# nrf7120E_enga_flpr register map
Vendor: Nordic Semiconductor; Series: nrf71; File version: 1
Registers are 32-bit, read-write, reset 0x0 unless marked. A register's access mark holds for its fields unless they carry their own. Offsets are from the block's base; [hi:lo] are bit positions; lines under a group give offsets from that group; {n}, {i} and the like mark numbered series; 'fields as' and 'values as' point back to an identical list.

## GLOBAL_WICR_NS — Wi-Fi Information Configuration Registers
Base 0x003FD000
0x00 FIRMWARE group — Unspecified
  0x00 LMACINITPC reset 0x28080000 — Boot address for LMAC processor (defaults to start of Wi-Fi core ROM_0)
    [31:0] INITPC — LMAC boot vector
  0x04 UMACINITPC reset 0x28180000 — Boot address for UMAC processor (defaults to start of Wi-Fi core ROM_1)
    [31:0] INITPC — UMAC boot vector
  0x08 LMACROMPATCHADDR — Address in MRAM for LMAC ROM patch
    [31:0] Address — LMAC ROM patch address
  0x0C UMACROMPATCHADDR — Address in MRAM for UMAC ROM patch
    [31:0] Address — UMAC ROM patch address
0x80 IPCCONFIG group — Unspecified
  0x00 COMMANDMBOXADDR — Base address of command mailbox
    [31:0] ADDRESS — Base address of mailbox
  0x04 COMMANDMBOXSIZE — Size of command mailbox in bytes
    [31:0] SIZE — Size in bytes
  0x08 EVENTMBOXADDR — Base address of event mailbox
    [31:0] ADDRESS — Base address of mailbox
  0x0C EVENTMBOXSIZE — Size of event mailbox in bytes
    [31:0] SIZE — Size in bytes
  0x10 SPAREMBOXADDR — Base address of spare mailbox
    [31:0] ADDRESS — Base address of mailbox
  0x14 SPAREMBOXSIZE — Size of spare mailbox in bytes
    [31:0] SIZE — Size in bytes
0x100 VTFDATA reset 0xFFFFFFFF — Pointer to memory location containing VTF data from the VTF monitoring system
  [31:0] ADDRESS — Address of the VTF monitoring data in RAM
0x104 RFPARAMSDATAADDR — Base address of RF parameter data
  [31:0] ADDRESS
0x108 RFPARAMSDATASIZE — Size of RF parameter data in bytes
  [31:0] SIZE — Size in bytes

## VPRCLIC_NS — VPR CLIC registers
Base 0xF0000000
0x00 CLIC group — Unspecified
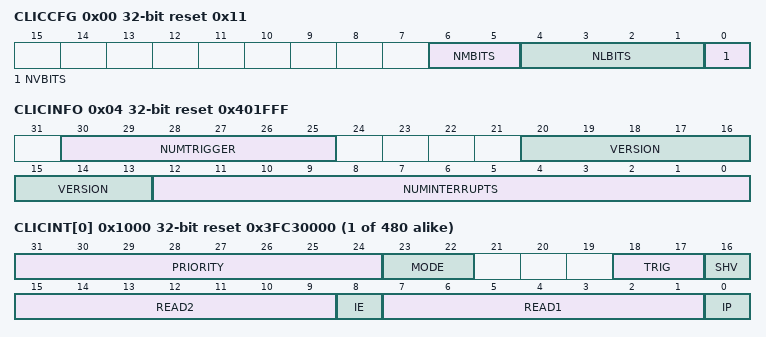
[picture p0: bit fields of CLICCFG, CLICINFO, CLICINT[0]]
  0x00 CLICCFG ro reset 0x11 — CLIC configuration.
    [6:5] NMBITS — Interrupt privilege mode.
      0=ModeM (All interrupts are M-mode only)
    [4:1] NLBITS — Interrupt level encoding.
      8=Eight (8 bits = interrupt levels encoded in eight bits)
    [0] NVBITS — Selective interrupt hardware vectoring.
      1=Implemented (Selective interrupt hardware vectoring is implemented)
  0x04 CLICINFO ro reset 0x401FFF — CLIC information.
    [30:25] NUMTRIGGER — Number of maximum interrupt triggers supported
    [20:13] VERSION
    [12:0] NUMINTERRUPTS — Maximum number of interrupts supported.
  {0x1000+4j} CLICINT[{j}] (j=0..479) reset 0x3FC30000 — Description collection: Interrupt control register for IRQ number [n].
    [31:24] PRIORITY — Interrupt priority level
      63=PRIO3F (Priority level 0x3F); 127=PRIO7F (Priority level 0x7F); 191=PRIOBF (Priority level 0xBF); 255=PRIOFF (Priority level 0xFF); 63=PRIOLEVEL0 (Deprecated enumerator - Priority level 0); 127=PRIOLEVEL1 (Deprecated enumerator - Priority level 1); 191=PRIOLEVEL2 (Deprecated enumerator - Priority level 2); 255=PRIOLEVEL3 (Deprecated enumerator - Priority level 3)
    [23:22] MODE ro — Privilege mode.
      3=MachineMode
    [18:17] TRIG ro — Trigger type and polarity for each interrupt input.
      1=EdgeTriggered (Interrupts are edge-triggered)
    [16] SHV ro — Selective Hardware Vectoring.
      1=Vectored (Hardware vectored)
    [15:9] READ2 ro — Read as 0, write ignored.
    [8] IE — Interrupt enable bit.
      0=Disabled (Interrupt disabled); 1=Enabled (Interrupt enabled)
    [7:1] READ1 ro — Read as 0, write ignored.
    [0] IP — Interrupt Pending bit.
      0=NotPending (Interrupt not pending); 1=Pending (Interrupt pending)

## GLOBAL_DPPIC00_NS — Distributed programmable peripheral interconnect controller 0
Base 0x40042000; alternate view of GLOBAL_USBHSCORE_NS
Same registers: GLOBAL_DPPIC10_NS 0x40082000, GLOBAL_DPPIC20_NS 0x400C2000, GLOBAL_DPPIC30_NS 0x40102000, GLOBAL_DPPIC00_S 0x50042000 (alternate view of GLOBAL_USBHSCORE_S), GLOBAL_DPPIC10_S 0x50082000, GLOBAL_DPPIC20_S 0x500C2000, GLOBAL_DPPIC30_S 0x50102000
{0x0+8i} TASKS_CHG[{i}] (i=0..5) group — Channel group tasks
  0x00 EN wo — Description cluster: Enable channel group n
    [0] EN — Enable channel group n
      1=Trigger task
  0x04 DIS wo — Description cluster: Disable channel group n
    [0] DIS — Disable channel group n
      1=Trigger task
{0x80+8i} SUBSCRIBE_CHG[{i}] (i=0..5) group — Subscribe configuration for tasks
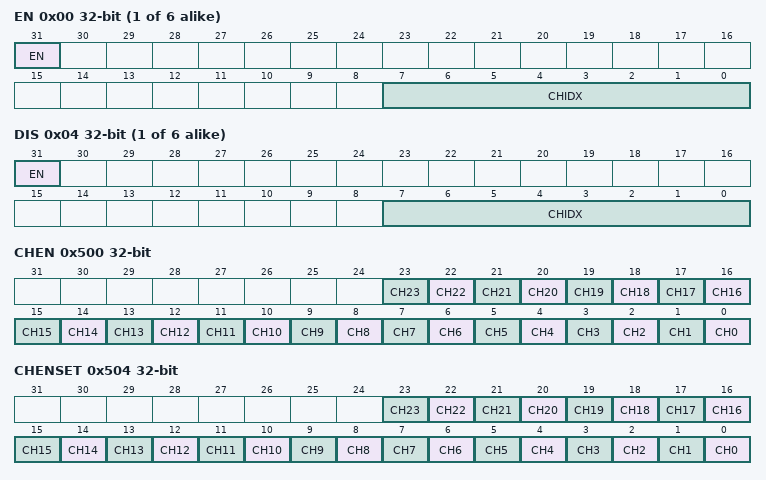
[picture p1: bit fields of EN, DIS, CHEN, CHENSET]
  0x00 EN — Description cluster: Subscribe configuration for task CHG[n].EN
    [31] EN
      0=Disabled (Disable subscription); 1=Enabled (Enable subscription)
    [7:0] CHIDX — DPPI channel that task CHG[n].EN will subscribe to
  0x04 DIS — Description cluster: Subscribe configuration for task CHG[n].DIS
    [31] EN
      values as SUBSCRIBE_CHG[0].EN.EN
    [7:0] CHIDX — DPPI channel that task CHG[n].DIS will subscribe to
0x500 CHEN — Channel enable register
  [all] fields
    0=Disabled (Disable channel); 1=Enabled (Enable channel)
  [n] CH{n} (n=0..23) — Enable or disable channel {n}
0x504 CHENSET write-1-sets — Channel enable set register
  [all] fields
    on read: 0=Disabled (Read: Channel disabled); 1=Enabled (Read: Channel enabled) | on write: 1=Set (Write: Enable channel)
  [n] CH{n} (n=0..23) — Channel {n} enable set register. Writing 0 has no effect.
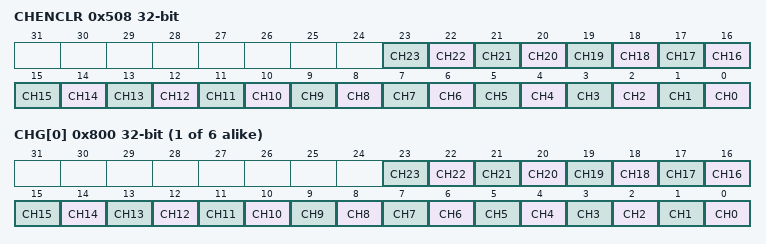
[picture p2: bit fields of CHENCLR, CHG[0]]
0x508 CHENCLR write-1-clears — Channel enable clear register
  [all] fields
    on read: 0=Disabled (Read: Channel disabled); 1=Enabled (Read: Channel enabled) | on write: 1=Clear (Write: Disable channel)
  [n] CH{n} (n=0..23) — Channel {n} enable clear register. Writing 0 has no effect.
{0x800+4i} CHG[{i}] (i=0..5) — Description collection: Channel group n Note: Writes to this register are ignored if either SUBSCRIBE_CHG[n].EN or SUBSCRIBE_CHG[n].DIS is enabled
  [all] fields
    0=Excluded; 1=Included
  [n] CH{n} (n=0..23) — Include or exclude channel {n}

## Notices in the file
Copyright (c) 2010 - 2026, Nordic Semiconductor ASA All rights reserved.
SPDX-License-Identifier: BSD-3-Clause
Redistribution and use in source and binary forms, with or without
modification, are permitted provided that the following conditions are met:
1. Redistributions of source code must retain the above copyright notice, this
list of conditions and the following disclaimer.
2. Redistributions in binary form must reproduce the above copyright
notice, this list of conditions and the following disclaimer in the
documentation and/or other materials provided with the distribution.
3. Neither the name of Nordic Semiconductor ASA nor the names of its
contributors may be used to endorse or promote products derived from this
software without specific prior written permission.
THIS SOFTWARE IS PROVIDED BY THE COPYRIGHT HOLDERS AND CONTRIBUTORS "AS IS"
AND ANY EXPRESS OR IMPLIED WARRANTIES, INCLUDING, BUT NOT LIMITED TO, THE
IMPLIED WARRANTIES OF MERCHANTABILITY, AND FITNESS FOR A PARTICULAR PURPOSE
ARE DISCLAIMED. IN NO EVENT SHALL NORDIC SEMICONDUCTOR ASA OR CONTRIBUTORS BE
LIABLE FOR ANY DIRECT, INDIRECT, INCIDENTAL, SPECIAL, EXEMPLARY, OR
CONSEQUENTIAL DAMAGES (INCLUDING, BUT NOT LIMITED TO, PROCUREMENT OF
SUBSTITUTE GOODS OR SERVICES; LOSS OF USE, DATA, OR PROFITS; OR BUSINESS
INTERRUPTION) HOWEVER CAUSED AND ON ANY THEORY OF LIABILITY, WHETHER IN
CONTRACT, STRICT LIABILITY, OR TORT (INCLUDING NEGLIGENCE OR OTHERWISE)
ARISING IN ANY WAY OUT OF THE USE OF THIS SOFTWARE, EVEN IF ADVISED OF THE
POSSIBILITY OF SUCH DAMAGE.
